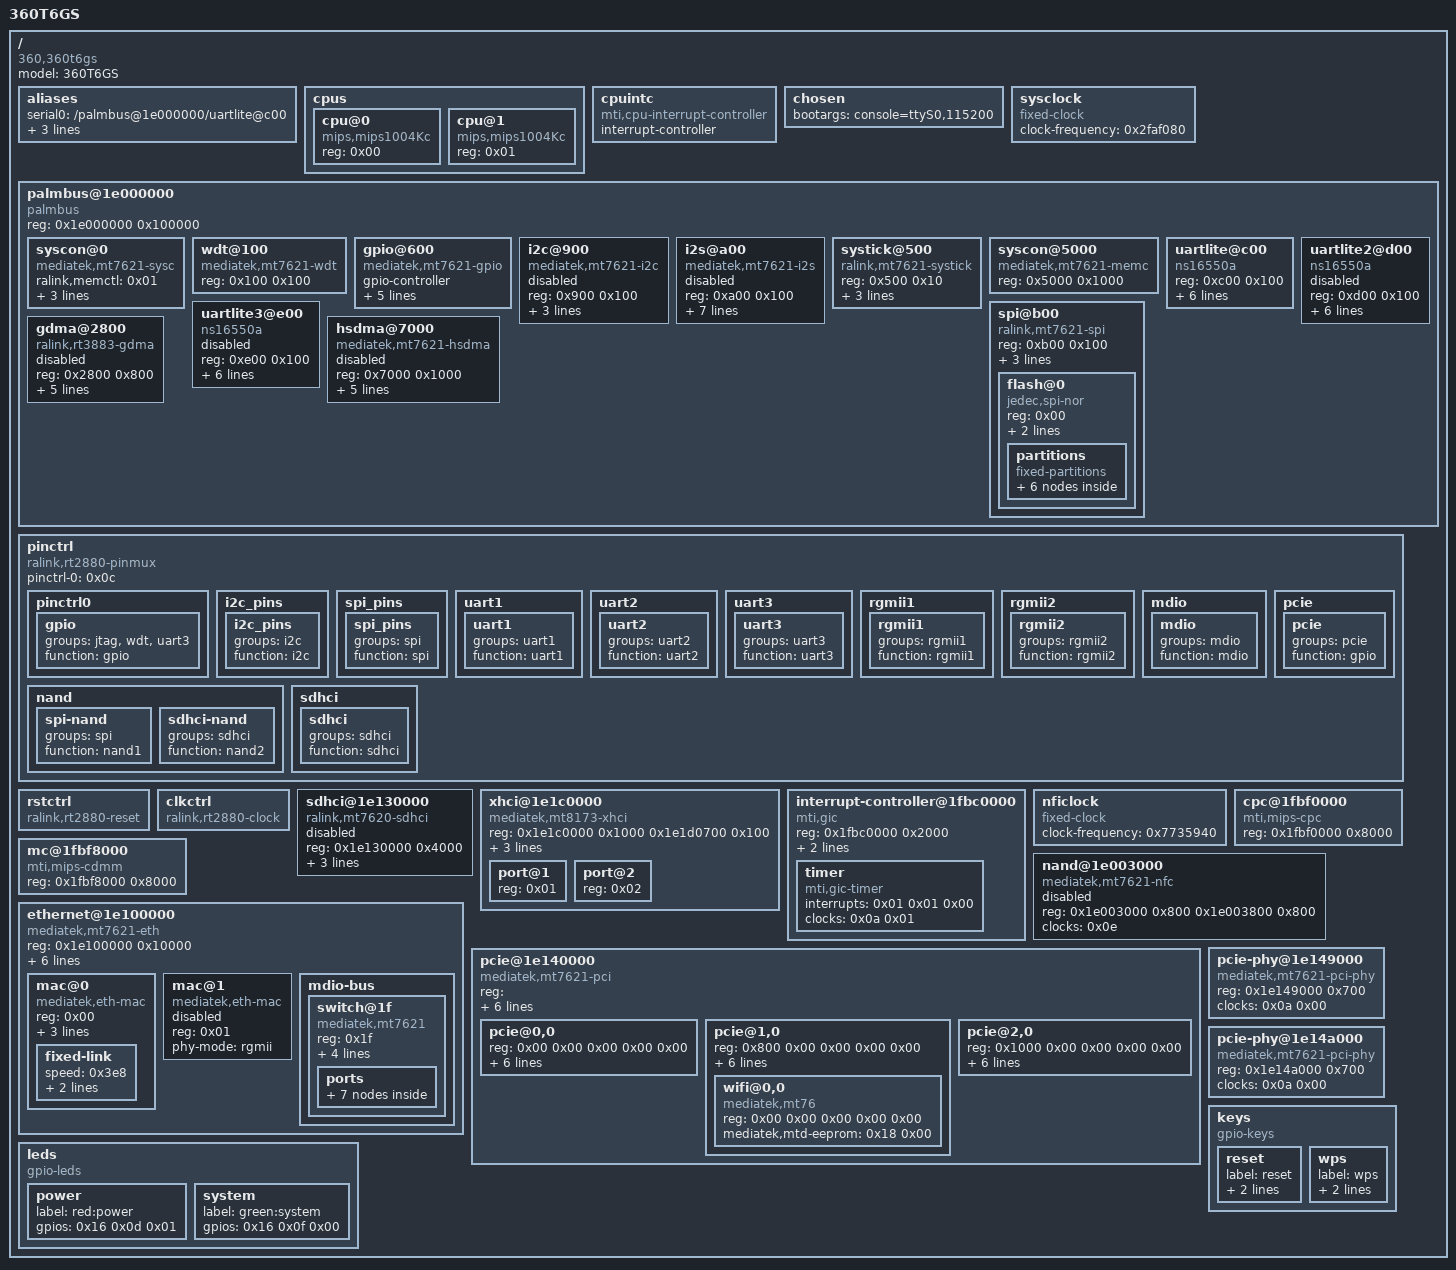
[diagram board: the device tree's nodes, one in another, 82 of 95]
/dts-v1/;

/ {
        #address-cells = <0x01>;
        #size-cells = <0x01>;
        compatible = "360,360t6gs", "mediatek,mt7621-soc";
        model = "360T6GS";

        aliases {
                serial0 = "/palmbus@1e000000/uartlite@c00";
                led-boot = "/leds/system";
                led-failsafe = "/leds/system";
                led-upgrade = "/leds/system";
        };

        cpus {
                #address-cells = <0x01>;
                #size-cells = <0x00>;

                cpu@0 {
                        device_type = "cpu";
                        compatible = "mips,mips1004Kc";
                        reg = <0x00>;
                };

                cpu@1 {
                        device_type = "cpu";
                        compatible = "mips,mips1004Kc";
                        reg = <0x01>;
                };
        };

        cpuintc {
                #address-cells = <0x00>;
                #interrupt-cells = <0x01>;
                interrupt-controller;
                compatible = "mti,cpu-interrupt-controller";
        };

        chosen {
                bootargs = "console=ttyS0,115200";
        };

        sysclock {
                #clock-cells = <0x00>;
                compatible = "fixed-clock";
                clock-frequency = <0x2faf080>;
                phandle = <0x04>;
        };

        palmbus@1e000000 {
                compatible = "palmbus";
                reg = <0x1e000000 0x100000>;
                ranges = <0x00 0x1e000000 0xfffff>;
                #address-cells = <0x01>;
                #size-cells = <0x01>;

                syscon@0 {
                        compatible = "mediatek,mt7621-sysc", "syscon";
                        #clock-cells = <0x01>;
                        ralink,memctl = <0x01>;
                        clock-output-names = "xtal", "cpu", "bus", "50m", "125m", "150m", "250m", "270m";
                        reg = <0x00 0x100>;
                        phandle = <0x0a>;
                };

                wdt@100 {
                        compatible = "mediatek,mt7621-wdt";
                        reg = <0x100 0x100>;
                };

                gpio@600 {
                        #gpio-cells = <0x02>;
                        #interrupt-cells = <0x02>;
                        compatible = "mediatek,mt7621-gpio";
                        gpio-controller;
                        gpio-ranges = <0x02 0x00 0x00 0x5f>;
                        interrupt-controller;
                        reg = <0x600 0x100>;
                        interrupt-parent = <0x03>;
                        interrupts = <0x00 0x0c 0x04>;
                        phandle = <0x16>;
                };

                i2c@900 {
                        compatible = "mediatek,mt7621-i2c";
                        reg = <0x900 0x100>;
                        clocks = <0x04>;
                        resets = <0x05 0x10>;
                        reset-names = "i2c";
                        #address-cells = <0x01>;
                        #size-cells = <0x00>;
                        status = "disabled";
                        pinctrl-names = "default";
                        pinctrl-0 = <0x06>;
                };

                i2s@a00 {
                        compatible = "mediatek,mt7621-i2s";
                        reg = <0xa00 0x100>;
                        clocks = <0x04>;
                        resets = <0x05 0x11>;
                        reset-names = "i2s";
                        interrupt-parent = <0x03>;
                        interrupts = <0x00 0x10 0x04>;
                        txdma-req = <0x02>;
                        rxdma-req = <0x03>;
                        dmas = <0x07 0x04 0x07 0x06>;
                        dma-names = "tx", "rx";
                        status = "disabled";
                };

                systick@500 {
                        compatible = "ralink,mt7621-systick", "ralink,cevt-systick";
                        reg = <0x500 0x10>;
                        resets = <0x05 0x1c>;
                        reset-names = "intc";
                        interrupt-parent = <0x03>;
                        interrupts = <0x00 0x05 0x04>;
                };

                syscon@5000 {
                        compatible = "mediatek,mt7621-memc", "syscon";
                        reg = <0x5000 0x1000>;
                        phandle = <0x01>;
                };

                uartlite@c00 {
                        compatible = "ns16550a";
                        reg = <0xc00 0x100>;
                        clock-frequency = <0x2faf080>;
                        interrupt-parent = <0x03>;
                        interrupts = <0x00 0x1a 0x04>;
                        reg-shift = <0x02>;
                        reg-io-width = <0x04>;
                        no-loopback-test;
                };

                uartlite2@d00 {
                        compatible = "ns16550a";
                        reg = <0xd00 0x100>;
                        clock-frequency = <0x2faf080>;
                        interrupt-parent = <0x03>;
                        interrupts = <0x00 0x1b 0x04>;
                        reg-shift = <0x02>;
                        reg-io-width = <0x04>;
                        pinctrl-names = "default";
                        pinctrl-0 = <0x08>;
                        status = "disabled";
                };

                uartlite3@e00 {
                        compatible = "ns16550a";
                        reg = <0xe00 0x100>;
                        clock-frequency = <0x2faf080>;
                        interrupt-parent = <0x03>;
                        interrupts = <0x00 0x1c 0x04>;
                        reg-shift = <0x02>;
                        reg-io-width = <0x04>;
                        pinctrl-names = "default";
                        pinctrl-0 = <0x09>;
                        status = "disabled";
                };

                spi@b00 {
                        status = "okay";
                        compatible = "ralink,mt7621-spi";
                        reg = <0xb00 0x100>;
                        clocks = <0x0a 0x02>;
                        resets = <0x05 0x12>;
                        reset-names = "spi";
                        #address-cells = <0x01>;
                        #size-cells = <0x00>;
                        pinctrl-names = "default";
                        pinctrl-0 = <0x0b>;

                        flash@0 {
                                compatible = "jedec,spi-nor";
                                reg = <0x00>;
                                spi-max-frequency = <0x4c4b400>;
                                m25p,fast-read;

                                partitions {
                                        compatible = "fixed-partitions";
                                        #address-cells = <0x01>;
                                        #size-cells = <0x01>;

                                        partition@0 {
                                                label = "bootloader";
                                                reg = <0x00 0x30000>;
                                                read-only;
                                        };

                                        partition@30000 {
                                                label = "config";
                                                reg = <0x30000 0x10000>;
                                                read-only;
                                        };

                                        partition@40000 {
                                                label = "factory";
                                                reg = <0x40000 0x10000>;
                                                read-only;
                                                compatible = "nvmem-cells";
                                                #address-cells = <0x01>;
                                                #size-cells = <0x01>;
                                                phandle = <0x18>;

                                                macaddr@e000 {
                                                        reg = <0xe000 0x06>;
                                                        phandle = <0x12>;
                                                };

                                                macaddr@e006 {
                                                        reg = <0xe006 0x06>;
                                                        phandle = <0x13>;
                                                };
                                        };

                                        partition@50000 {
                                                compatible = "denx,uimage";
                                                label = "firmware";
                                                reg = <0x50000 0xfb0000>;
                                        };
                                };
                        };
                };

                gdma@2800 {
                        compatible = "ralink,rt3883-gdma";
                        reg = <0x2800 0x800>;
                        resets = <0x05 0x0e>;
                        reset-names = "dma";
                        interrupt-parent = <0x03>;
                        interrupts = <0x00 0x0d 0x04>;
                        #dma-cells = <0x01>;
                        #dma-channels = <0x10>;
                        #dma-requests = <0x10>;
                        status = "disabled";
                        phandle = <0x07>;
                };

                hsdma@7000 {
                        compatible = "mediatek,mt7621-hsdma";
                        reg = <0x7000 0x1000>;
                        resets = <0x05 0x05>;
                        reset-names = "hsdma";
                        interrupt-parent = <0x03>;
                        interrupts = <0x00 0x0b 0x04>;
                        #dma-cells = <0x01>;
                        #dma-channels = <0x01>;
                        #dma-requests = <0x01>;
                        status = "disabled";
                };
        };

        pinctrl {
                compatible = "ralink,rt2880-pinmux";
                pinctrl-names = "default";
                pinctrl-0 = <0x0c>;
                phandle = <0x02>;

                pinctrl0 {
                        phandle = <0x0c>;

                        gpio {
                                groups = "jtag", "wdt", "uart3";
                                function = "gpio";
                        };
                };

                i2c_pins {
                        phandle = <0x06>;

                        i2c_pins {
                                groups = "i2c";
                                function = "i2c";
                        };
                };

                spi_pins {
                        phandle = <0x0b>;

                        spi_pins {
                                groups = "spi";
                                function = "spi";
                        };
                };

                uart1 {

                        uart1 {
                                groups = "uart1";
                                function = "uart1";
                        };
                };

                uart2 {
                        phandle = <0x08>;

                        uart2 {
                                groups = "uart2";
                                function = "uart2";
                        };
                };

                uart3 {
                        phandle = <0x09>;

                        uart3 {
                                groups = "uart3";
                                function = "uart3";
                        };
                };

                rgmii1 {
                        phandle = <0x10>;

                        rgmii1 {
                                groups = "rgmii1";
                                function = "rgmii1";
                        };
                };

                rgmii2 {
                        phandle = <0x11>;

                        rgmii2 {
                                groups = "rgmii2";
                                function = "rgmii2";
                        };
                };

                mdio {
                        phandle = <0x0f>;

                        mdio {
                                groups = "mdio";
                                function = "mdio";
                        };
                };

                pcie {
                        phandle = <0x15>;

                        pcie {
                                groups = "pcie";
                                function = "gpio";
                        };
                };

                nand {

                        spi-nand {
                                groups = "spi";
                                function = "nand1";
                        };

                        sdhci-nand {
                                groups = "sdhci";
                                function = "nand2";
                        };
                };

                sdhci {
                        phandle = <0x0d>;

                        sdhci {
                                groups = "sdhci";
                                function = "sdhci";
                        };
                };
        };

        rstctrl {
                compatible = "ralink,rt2880-reset";
                #reset-cells = <0x01>;
                phandle = <0x05>;
        };

        clkctrl {
                compatible = "ralink,rt2880-clock";
                #clock-cells = <0x01>;
        };

        sdhci@1e130000 {
                status = "disabled";
                compatible = "ralink,mt7620-sdhci";
                reg = <0x1e130000 0x4000>;
                interrupt-parent = <0x03>;
                interrupts = <0x00 0x14 0x04>;
                pinctrl-names = "default";
                pinctrl-0 = <0x0d>;
        };

        xhci@1e1c0000 {
                #address-cells = <0x01>;
                #size-cells = <0x00>;
                compatible = "mediatek,mt8173-xhci";
                reg = <0x1e1c0000 0x1000 0x1e1d0700 0x100>;
                reg-names = "mac", "ippc";
                clocks = <0x04>;
                clock-names = "sys_ck";
                interrupt-parent = <0x03>;
                interrupts = <0x00 0x16 0x04>;

                port@1 {
                        reg = <0x01>;
                        #trigger-source-cells = <0x00>;
                };

                port@2 {
                        reg = <0x02>;
                        #trigger-source-cells = <0x00>;
                };
        };

        interrupt-controller@1fbc0000 {
                compatible = "mti,gic";
                reg = <0x1fbc0000 0x2000>;
                interrupt-controller;
                #interrupt-cells = <0x03>;
                mti,reserved-cpu-vectors = <0x07>;
                phandle = <0x03>;

                timer {
                        compatible = "mti,gic-timer";
                        interrupts = <0x01 0x01 0x00>;
                        clocks = <0x0a 0x01>;
                };
        };

        nficlock {
                #clock-cells = <0x00>;
                compatible = "fixed-clock";
                clock-frequency = <0x7735940>;
                phandle = <0x0e>;
        };

        cpc@1fbf0000 {
                compatible = "mti,mips-cpc";
                reg = <0x1fbf0000 0x8000>;
        };

        mc@1fbf8000 {
                compatible = "mti,mips-cdmm";
                reg = <0x1fbf8000 0x8000>;
        };

        nand@1e003000 {
                status = "disabled";
                compatible = "mediatek,mt7621-nfc";
                reg = <0x1e003000 0x800 0x1e003800 0x800>;
                reg-names = "nfi", "ecc";
                clocks = <0x0e>;
                clock-names = "nfi_clk";
        };

        ethernet@1e100000 {
                compatible = "mediatek,mt7621-eth";
                reg = <0x1e100000 0x10000>;
                clocks = <0x0a 0x09 0x0a 0x16>;
                clock-names = "fe", "ethif";
                #address-cells = <0x01>;
                #size-cells = <0x00>;
                resets = <0x05 0x06 0x05 0x17>;
                reset-names = "fe", "eth";
                interrupt-parent = <0x03>;
                interrupts = <0x00 0x03 0x04>;
                mediatek,ethsys = <0x0a>;
                pinctrl-names = "default";
                pinctrl-0 = <0x0f 0x10 0x11>;

                mac@0 {
                        compatible = "mediatek,eth-mac";
                        reg = <0x00>;
                        phy-mode = "rgmii";
                        nvmem-cells = <0x12>;
                        nvmem-cell-names = "mac-address";
                        phandle = <0x14>;

                        fixed-link {
                                speed = <0x3e8>;
                                full-duplex;
                                pause;
                        };
                };

                mac@1 {
                        compatible = "mediatek,eth-mac";
                        reg = <0x01>;
                        status = "disabled";
                        phy-mode = "rgmii";
                };

                mdio-bus {
                        #address-cells = <0x01>;
                        #size-cells = <0x00>;

                        switch@1f {
                                compatible = "mediatek,mt7621";
                                reg = <0x1f>;
                                mediatek,mcm;
                                resets = <0x05 0x02>;
                                reset-names = "mcm";
                                interrupt-controller;
                                #interrupt-cells = <0x01>;
                                interrupts = <0x00 0x17 0x04>;

                                ports {
                                        #address-cells = <0x01>;
                                        #size-cells = <0x00>;

                                        port@0 {
                                                status = "okay";
                                                reg = <0x00>;
                                                label = "lan3";
                                        };

                                        port@1 {
                                                status = "okay";
                                                reg = <0x01>;
                                                label = "lan2";
                                        };

                                        port@2 {
                                                status = "okay";
                                                reg = <0x02>;
                                                label = "lan1";
                                        };

                                        port@3 {
                                                status = "okay";
                                                reg = <0x03>;
                                                label = "wan";
                                                nvmem-cells = <0x13>;
                                                nvmem-cell-names = "mac-address";
                                        };

                                        port@4 {
                                                status = "disabled";
                                                reg = <0x04>;
                                                label = "lan4";
                                        };

                                        port@6 {
                                                reg = <0x06>;
                                                ethernet = <0x14>;
                                                phy-mode = "rgmii";

                                                fixed-link {
                                                        speed = <0x3e8>;
                                                        full-duplex;
                                                        pause;
                                                };
                                        };
                                };
                        };
                };
        };

        pcie@1e140000 {
                compatible = "mediatek,mt7621-pci";
                reg = <0x1e140000 0x100 0x1e142000 0x100 0x1e143000 0x100 0x1e144000 0x100>;
                #address-cells = <0x03>;
                #size-cells = <0x02>;
                pinctrl-names = "default";
                pinctrl-0 = <0x15>;
                device_type = "pci";
                ranges = <0x2000000 0x00 0x60000000 0x60000000 0x00 0x10000000 0x1000000 0x00 0x00 0x1e160000 0x00 0x10000>;
                status = "okay";
                #interrupt-cells = <0x01>;
                interrupt-map-mask = <0xf800 0x00 0x00 0x00>;
                interrupt-map = <0x00 0x00 0x00 0x00 0x03 0x00 0x04 0x04 0x800 0x00 0x00 0x00 0x03 0x00 0x18 0x04 0x1000 0x00 0x00 0x00 0x03 0x00 0x19 0x04>;
                reset-gpios = <0x16 0x13 0x01>;

                pcie@0,0 {
                        reg = <0x00 0x00 0x00 0x00 0x00>;
                        #address-cells = <0x03>;
                        #size-cells = <0x02>;
                        device_type = "pci";
                        ranges;
                        #interrupt-cells = <0x01>;
                        interrupt-map-mask = <0x00 0x00 0x00 0x00>;
                        interrupt-map = <0x00 0x00 0x00 0x00 0x03 0x00 0x04 0x04>;
                        resets = <0x05 0x18>;
                        clocks = <0x0a 0x17>;
                        phys = <0x17 0x01>;
                        phy-names = "pcie-phy0";
                };

                pcie@1,0 {
                        reg = <0x800 0x00 0x00 0x00 0x00>;
                        #address-cells = <0x03>;
                        #size-cells = <0x02>;
                        device_type = "pci";
                        ranges;
                        #interrupt-cells = <0x01>;
                        interrupt-map-mask = <0x00 0x00 0x00 0x00>;
                        interrupt-map = <0x00 0x00 0x00 0x00 0x03 0x00 0x18 0x04>;
                        resets = <0x05 0x19>;
                        clocks = <0x0a 0x18>;
                        phys = <0x17 0x01>;
                        phy-names = "pcie-phy1";

                        wifi@0,0 {
                                compatible = "mediatek,mt76";
                                reg = <0x00 0x00 0x00 0x00 0x00>;
                                mediatek,mtd-eeprom = <0x18 0x00>;
                        };
                };

                pcie@2,0 {
                        reg = <0x1000 0x00 0x00 0x00 0x00>;
                        #address-cells = <0x03>;
                        #size-cells = <0x02>;
                        device_type = "pci";
                        ranges;
                        #interrupt-cells = <0x01>;
                        interrupt-map-mask = <0x00 0x00 0x00 0x00>;
                        interrupt-map = <0x00 0x00 0x00 0x00 0x03 0x00 0x19 0x04>;
                        resets = <0x05 0x1a>;
                        clocks = <0x0a 0x19>;
                        phys = <0x19 0x00>;
                        phy-names = "pcie-phy2";
                };
        };

        pcie-phy@1e149000 {
                compatible = "mediatek,mt7621-pci-phy";
                reg = <0x1e149000 0x700>;
                clocks = <0x0a 0x00>;
                #phy-cells = <0x01>;
                phandle = <0x17>;
        };

        pcie-phy@1e14a000 {
                compatible = "mediatek,mt7621-pci-phy";
                reg = <0x1e14a000 0x700>;
                clocks = <0x0a 0x00>;
                #phy-cells = <0x01>;
                phandle = <0x19>;
        };

        leds {
                compatible = "gpio-leds";

                power {
                        label = "red:power";
                        gpios = <0x16 0x0d 0x01>;
                };

                system {
                        label = "green:system";
                        gpios = <0x16 0x0f 0x00>;
                };
        };

        keys {
                compatible = "gpio-keys";

                reset {
                        label = "reset";
                        gpios = <0x16 0x07 0x01>;
                        linux,code = <0x198>;
                };

                wps {
                        label = "wps";
                        gpios = <0x16 0x06 0x01>;
                        linux,code = <0x211>;
                };
        };
};
